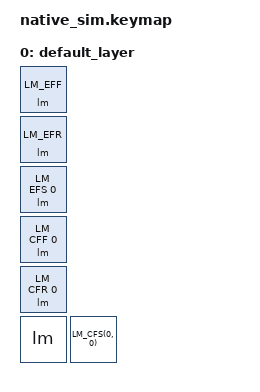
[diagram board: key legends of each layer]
#include <dt-bindings/zmk/keys.h>
#include <dt-bindings/zmk/kscan_mock.h>
#include <dt-bindings/zmk/led_matrix.h>
#include <dt-bindings/zmk/led_matrix_colors.h>
#include <dt-bindings/led/led.h>
#include <behaviors.dtsi>

/ {
    chosen {
        zmk,kscan = &kscan;
        zmk,led-matrix = &led_matrix;
    };

    kscan: native_posix_64_kscan_mock {
        compatible = "zmk,kscan-mock";
        rows = <2>;
        columns = <3>;
        exit-after;
        events = <
            ZMK_MOCK_PRESS(0,0,10)
            ZMK_MOCK_RELEASE(0,0,20)
            ZMK_MOCK_PRESS(0,1,50)
            ZMK_MOCK_RELEASE(0,1,20)
            ZMK_MOCK_PRESS(0,2,50)
            ZMK_MOCK_RELEASE(0,2,20)
            ZMK_MOCK_PRESS(1,0,50)
            ZMK_MOCK_RELEASE(1,0,20)
            ZMK_MOCK_PRESS(1,1,50)
            ZMK_MOCK_RELEASE(1,1,20)
            ZMK_MOCK_PRESS(1,2,50)
            ZMK_MOCK_RELEASE(1,2,20)
        >;
    };

    keymap {
        compatible = "zmk,keymap";

        default_layer {
            bindings = <
                &lm LM_EFF
                &lm LM_EFR
                &lm LM_EFS 0
                &lm LM_CFF 0
                &lm LM_CFR 0
                &lm LM_CFS(0, 0)
            >;
        };
    };

    led_matrix_dev: led_matrix_dev {
        compatible = "zmk,led-mock";
        mode = "color";

        led_0 { index = <0>; color-mapping = <LED_COLOR_ID_RED LED_COLOR_ID_GREEN LED_COLOR_ID_BLUE>; };
    };

    led_matrix: led_matrix {
        compatible = "zmk,led-matrix";
        led-driver = "matrix";
        led-device = <&led_matrix_dev>;
        led-count = <1>;
        hid-timeout-ms = <0>;
        hid-caps-leds = <0>;
        hid-caps-color-on = <0xFFFFFF>;
        hid-caps-color-off = <0x010203>;
    };
};
